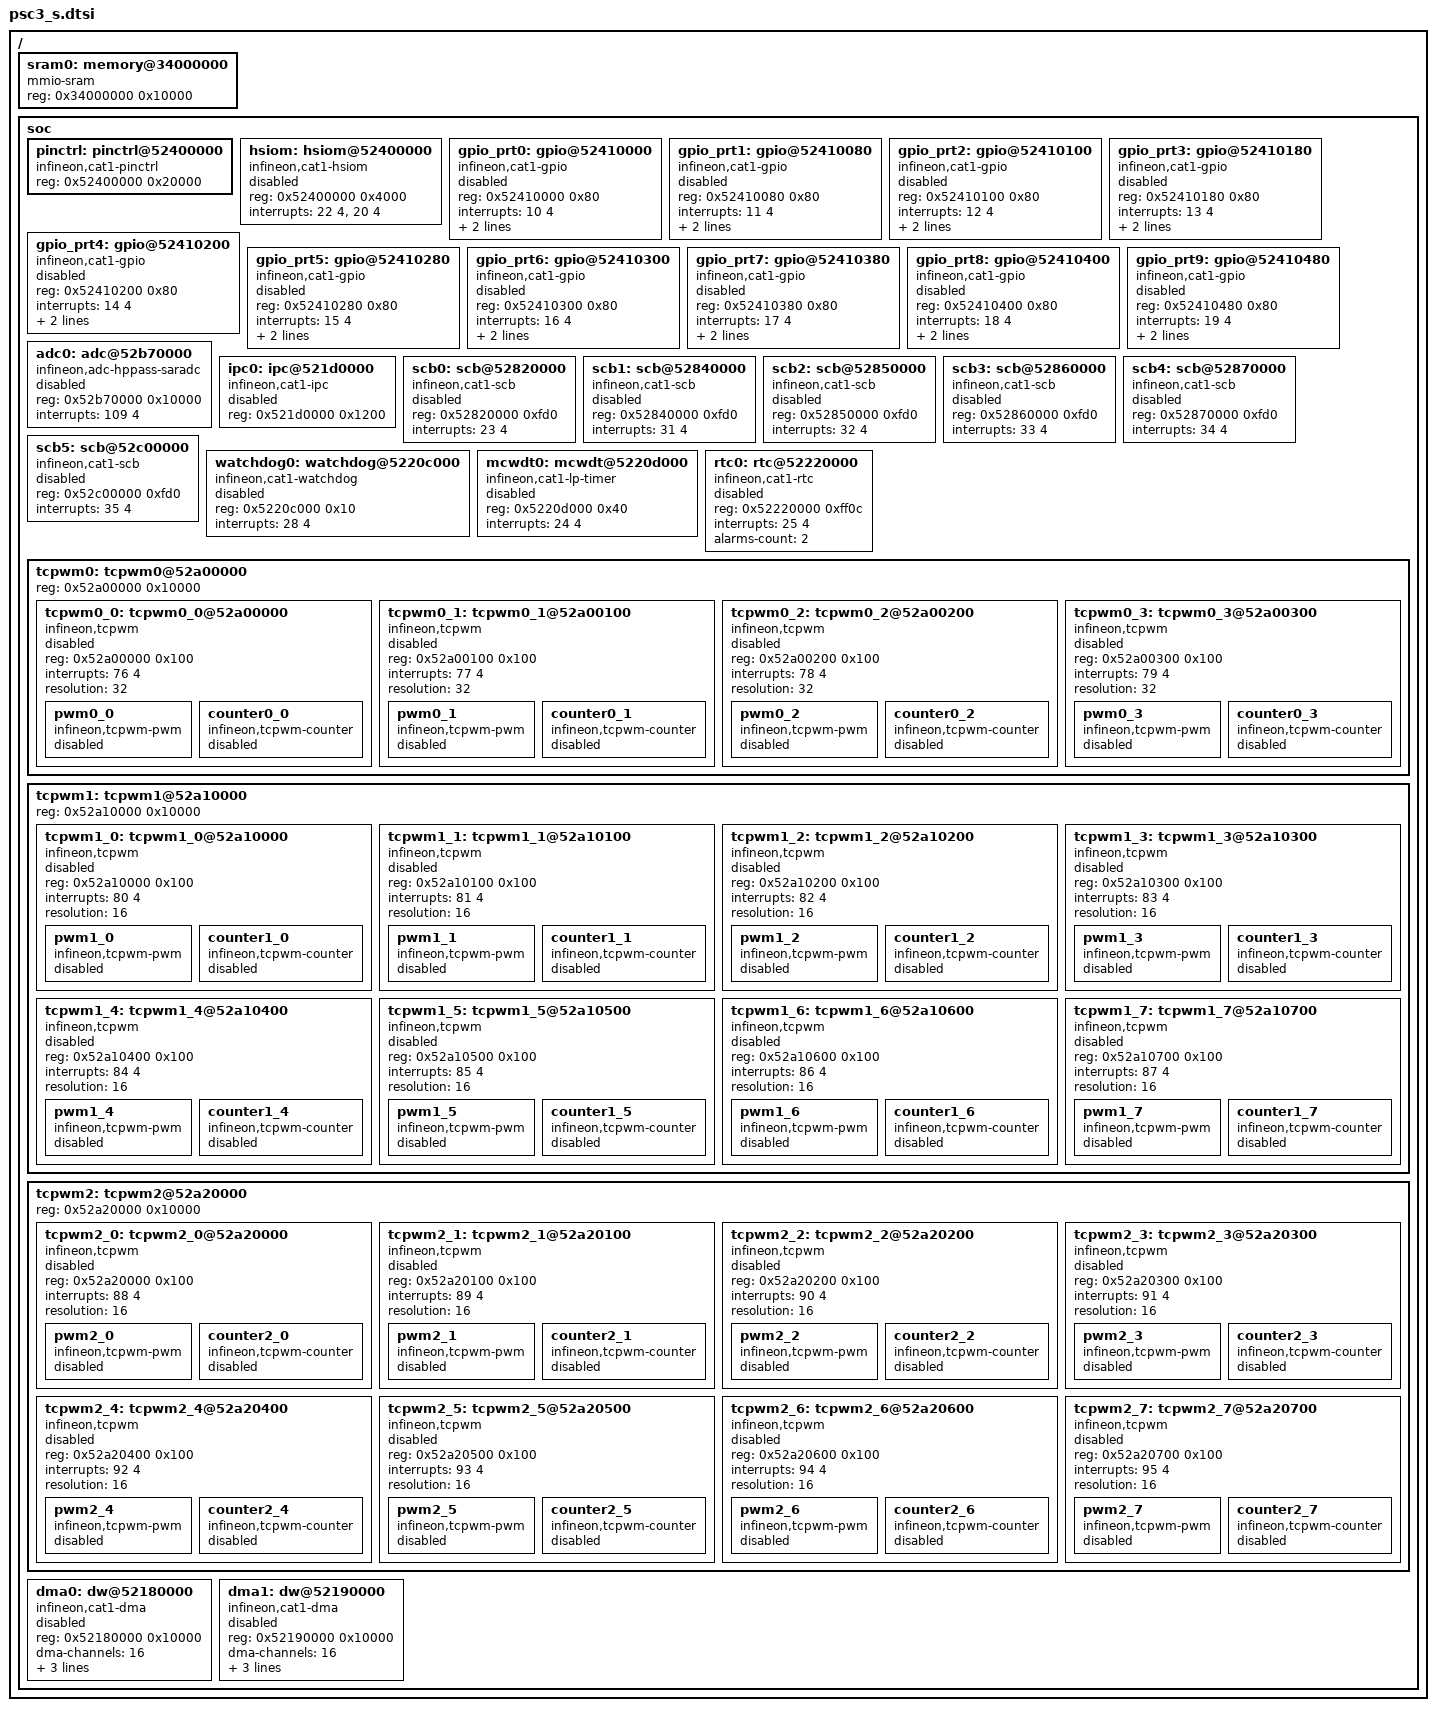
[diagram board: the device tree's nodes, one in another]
/*
 * copyright (c) (2016-2025), Cypress Semiconductor Corporation
 * (an Infineon company) or an affiliate of Cypress Semiconductor Corporation.
 *
 * SPDX-License-Identifier: Apache-2.0
 *
 */

#include <mem.h>
#include "psc3.cm33.dtsi"

/ {
	sram0: memory@34000000 {
		compatible = "mmio-sram";
		reg = <0x34000000 0x10000>;
	};

	soc {
		pinctrl: pinctrl@52400000 {
			compatible = "infineon,cat1-pinctrl";
			reg = <0x52400000 0x20000>;
		};

		hsiom: hsiom@52400000 {
			compatible = "infineon,cat1-hsiom";
			reg = <0x52400000 0x4000>;
			interrupts = <22 4>, <20 4>;
			status = "disabled";
		};

		gpio_prt0: gpio@52410000 {
			compatible = "infineon,cat1-gpio";
			reg = <0x52410000 0x80>;
			interrupts = <10 4>;
			gpio-controller;
			ngpios = <2>;
			status = "disabled";
			#gpio-cells = <2>;
		};

		gpio_prt1: gpio@52410080 {
			compatible = "infineon,cat1-gpio";
			reg = <0x52410080 0x80>;
			interrupts = <11 4>;
			gpio-controller;
			ngpios = <4>;
			status = "disabled";
			#gpio-cells = <2>;
		};

		gpio_prt2: gpio@52410100 {
			compatible = "infineon,cat1-gpio";
			reg = <0x52410100 0x80>;
			interrupts = <12 4>;
			gpio-controller;
			ngpios = <4>;
			status = "disabled";
			#gpio-cells = <2>;
		};

		gpio_prt3: gpio@52410180 {
			compatible = "infineon,cat1-gpio";
			reg = <0x52410180 0x80>;
			interrupts = <13 4>;
			gpio-controller;
			ngpios = <4>;
			status = "disabled";
			#gpio-cells = <2>;
		};

		gpio_prt4: gpio@52410200 {
			compatible = "infineon,cat1-gpio";
			reg = <0x52410200 0x80>;
			interrupts = <14 4>;
			gpio-controller;
			ngpios = <8>;
			status = "disabled";
			#gpio-cells = <2>;
		};

		gpio_prt5: gpio@52410280 {
			compatible = "infineon,cat1-gpio";
			reg = <0x52410280 0x80>;
			interrupts = <15 4>;
			gpio-controller;
			ngpios = <4>;
			status = "disabled";
			#gpio-cells = <2>;
		};

		gpio_prt6: gpio@52410300 {
			compatible = "infineon,cat1-gpio";
			reg = <0x52410300 0x80>;
			interrupts = <16 4>;
			gpio-controller;
			ngpios = <4>;
			status = "disabled";
			#gpio-cells = <2>;
		};

		gpio_prt7: gpio@52410380 {
			compatible = "infineon,cat1-gpio";
			reg = <0x52410380 0x80>;
			interrupts = <17 4>;
			gpio-controller;
			ngpios = <8>;
			status = "disabled";
			#gpio-cells = <2>;
		};

		gpio_prt8: gpio@52410400 {
			compatible = "infineon,cat1-gpio";
			reg = <0x52410400 0x80>;
			interrupts = <18 4>;
			gpio-controller;
			ngpios = <6>;
			status = "disabled";
			#gpio-cells = <2>;
		};

		gpio_prt9: gpio@52410480 {
			compatible = "infineon,cat1-gpio";
			reg = <0x52410480 0x80>;
			interrupts = <19 4>;
			gpio-controller;
			ngpios = <6>;
			status = "disabled";
			#gpio-cells = <2>;
		};

		adc0: adc@52b70000 {
			compatible = "infineon,adc-hppass-saradc";
			reg = <0x52b70000 0x10000>;
			interrupts = <109 4>;
			status = "disabled";
			#io-channel-cells = <1>;
		};

		ipc0: ipc@521d0000 {
			compatible = "infineon,cat1-ipc";
			reg = <0x521d0000 0x1200>;
			status = "disabled";
			#ipc-config-cells = <3>;
		};

		scb0: scb@52820000 {
			compatible = "infineon,cat1-scb";
			reg = <0x52820000 0xfd0>;
			interrupts = <23 4>;
			status = "disabled";
		};

		scb1: scb@52840000 {
			compatible = "infineon,cat1-scb";
			reg = <0x52840000 0xfd0>;
			interrupts = <31 4>;
			status = "disabled";
		};

		scb2: scb@52850000 {
			compatible = "infineon,cat1-scb";
			reg = <0x52850000 0xfd0>;
			interrupts = <32 4>;
			status = "disabled";
		};

		scb3: scb@52860000 {
			compatible = "infineon,cat1-scb";
			reg = <0x52860000 0xfd0>;
			interrupts = <33 4>;
			status = "disabled";
		};

		scb4: scb@52870000 {
			compatible = "infineon,cat1-scb";
			reg = <0x52870000 0xfd0>;
			interrupts = <34 4>;
			status = "disabled";
		};

		scb5: scb@52c00000 {
			compatible = "infineon,cat1-scb";
			reg = <0x52c00000 0xfd0>;
			interrupts = <35 4>;
			status = "disabled";
		};

		watchdog0: watchdog@5220c000 {
			compatible = "infineon,cat1-watchdog";
			reg = <0x5220c000 0x10>;
			interrupts = <28 4>;
			status = "disabled";
		};

		mcwdt0: mcwdt@5220d000 {
			compatible = "infineon,cat1-lp-timer";
			reg = <0x5220d000 0x40>;
			interrupts = <24 4>;
			status = "disabled";
		};

		rtc0: rtc@52220000 {
			compatible = "infineon,cat1-rtc";
			reg = <0x52220000 0xff0c>;
			interrupts = <25 4>;
			alarms-count = <2>;
			status = "disabled";
		};

		tcpwm0: tcpwm0@52a00000  {
			reg = <0x52a00000 0x10000>;
			#address-cells = <1>;
			#size-cells = <1>;

			tcpwm0_0: tcpwm0_0@52a00000 {
				compatible = "infineon,tcpwm";
				reg = <0x52a00000 0x100>;
				interrupts = <76 4>;
				resolution = <32>;
				status = "disabled";

				pwm0_0: pwm0_0 {
					compatible = "infineon,tcpwm-pwm";
					#pwm-cells = <3>;
					status = "disabled";
				};

				counter0_0: counter0_0 {
					compatible = "infineon,tcpwm-counter";
					status = "disabled";
				};
			};

			tcpwm0_1: tcpwm0_1@52a00100 {
				compatible = "infineon,tcpwm";
				reg = <0x52a00100 0x100>;
				interrupts = <77 4>;
				resolution = <32>;
				status = "disabled";

				pwm0_1: pwm0_1 {
					compatible = "infineon,tcpwm-pwm";
					#pwm-cells = <3>;
					status = "disabled";
				};

				counter0_1: counter0_1 {
					compatible = "infineon,tcpwm-counter";
					status = "disabled";
				};
			};

			tcpwm0_2: tcpwm0_2@52a00200 {
				compatible = "infineon,tcpwm";
				reg = <0x52a00200 0x100>;
				interrupts = <78 4>;
				resolution = <32>;
				status = "disabled";

				pwm0_2: pwm0_2 {
					compatible = "infineon,tcpwm-pwm";
					#pwm-cells = <3>;
					status = "disabled";
				};

				counter0_2: counter0_2 {
					compatible = "infineon,tcpwm-counter";
					status = "disabled";
				};
			};

			tcpwm0_3: tcpwm0_3@52a00300 {
				compatible = "infineon,tcpwm";
				reg = <0x52a00300 0x100>;
				interrupts = <79 4>;
				resolution = <32>;
				status = "disabled";

				pwm0_3: pwm0_3 {
					compatible = "infineon,tcpwm-pwm";
					#pwm-cells = <3>;
					status = "disabled";
				};

				counter0_3: counter0_3 {
					compatible = "infineon,tcpwm-counter";
					status = "disabled";
				};
			};
		};

		tcpwm1: tcpwm1@52a10000  {
			reg = <0x52a10000 0x10000>;
			#address-cells = <1>;
			#size-cells = <1>;

			tcpwm1_0: tcpwm1_0@52a10000 {
				compatible = "infineon,tcpwm";
				reg = <0x52a10000 0x100>;
				interrupts = <80 4>;
				resolution = <16>;
				status = "disabled";

				pwm1_0: pwm1_0 {
					compatible = "infineon,tcpwm-pwm";
					#pwm-cells = <3>;
					status = "disabled";
				};

				counter1_0: counter1_0 {
					compatible = "infineon,tcpwm-counter";
					status = "disabled";
				};
			};

			tcpwm1_1: tcpwm1_1@52a10100 {
				compatible = "infineon,tcpwm";
				reg = <0x52a10100 0x100>;
				interrupts = <81 4>;
				resolution = <16>;
				status = "disabled";

				pwm1_1: pwm1_1 {
					compatible = "infineon,tcpwm-pwm";
					#pwm-cells = <3>;
					status = "disabled";
				};

				counter1_1: counter1_1 {
					compatible = "infineon,tcpwm-counter";
					status = "disabled";
				};
			};

			tcpwm1_2: tcpwm1_2@52a10200 {
				compatible = "infineon,tcpwm";
				reg = <0x52a10200 0x100>;
				interrupts = <82 4>;
				resolution = <16>;
				status = "disabled";

				pwm1_2: pwm1_2 {
					compatible = "infineon,tcpwm-pwm";
					#pwm-cells = <3>;
					status = "disabled";
				};

				counter1_2: counter1_2 {
					compatible = "infineon,tcpwm-counter";
					status = "disabled";
				};
			};

			tcpwm1_3: tcpwm1_3@52a10300 {
				compatible = "infineon,tcpwm";
				reg = <0x52a10300 0x100>;
				interrupts = <83 4>;
				resolution = <16>;
				status = "disabled";

				pwm1_3: pwm1_3 {
					compatible = "infineon,tcpwm-pwm";
					#pwm-cells = <3>;
					status = "disabled";
				};

				counter1_3: counter1_3 {
					compatible = "infineon,tcpwm-counter";
					status = "disabled";
				};
			};

			tcpwm1_4: tcpwm1_4@52a10400 {
				compatible = "infineon,tcpwm";
				reg = <0x52a10400 0x100>;
				interrupts = <84 4>;
				resolution = <16>;
				status = "disabled";

				pwm1_4: pwm1_4 {
					compatible = "infineon,tcpwm-pwm";
					#pwm-cells = <3>;
					status = "disabled";
				};

				counter1_4: counter1_4 {
					compatible = "infineon,tcpwm-counter";
					status = "disabled";
				};
			};

			tcpwm1_5: tcpwm1_5@52a10500 {
				compatible = "infineon,tcpwm";
				reg = <0x52a10500 0x100>;
				interrupts = <85 4>;
				resolution = <16>;
				status = "disabled";

				pwm1_5: pwm1_5 {
					compatible = "infineon,tcpwm-pwm";
					#pwm-cells = <3>;
					status = "disabled";
				};

				counter1_5: counter1_5 {
					compatible = "infineon,tcpwm-counter";
					status = "disabled";
				};
			};

			tcpwm1_6: tcpwm1_6@52a10600 {
				compatible = "infineon,tcpwm";
				reg = <0x52a10600 0x100>;
				interrupts = <86 4>;
				resolution = <16>;
				status = "disabled";

				pwm1_6: pwm1_6 {
					compatible = "infineon,tcpwm-pwm";
					#pwm-cells = <3>;
					status = "disabled";
				};

				counter1_6: counter1_6 {
					compatible = "infineon,tcpwm-counter";
					status = "disabled";
				};
			};

			tcpwm1_7: tcpwm1_7@52a10700 {
				compatible = "infineon,tcpwm";
				reg = <0x52a10700 0x100>;
				interrupts = <87 4>;
				resolution = <16>;
				status = "disabled";

				pwm1_7: pwm1_7 {
					compatible = "infineon,tcpwm-pwm";
					#pwm-cells = <3>;
					status = "disabled";
				};

				counter1_7: counter1_7 {
					compatible = "infineon,tcpwm-counter";
					status = "disabled";
				};
			};
		};

		tcpwm2: tcpwm2@52a20000  {
			reg = <0x52a20000 0x10000>;
			#address-cells = <1>;
			#size-cells = <1>;

			tcpwm2_0: tcpwm2_0@52a20000 {
				compatible = "infineon,tcpwm";
				reg = <0x52a20000 0x100>;
				interrupts = <88 4>;
				resolution = <16>;
				status = "disabled";

				pwm2_0: pwm2_0 {
					compatible = "infineon,tcpwm-pwm";
					#pwm-cells = <3>;
					status = "disabled";
				};

				counter2_0: counter2_0 {
					compatible = "infineon,tcpwm-counter";
					status = "disabled";
				};
			};

			tcpwm2_1: tcpwm2_1@52a20100 {
				compatible = "infineon,tcpwm";
				reg = <0x52a20100 0x100>;
				interrupts = <89 4>;
				resolution = <16>;
				status = "disabled";

				pwm2_1: pwm2_1 {
					compatible = "infineon,tcpwm-pwm";
					#pwm-cells = <3>;
					status = "disabled";
				};

				counter2_1: counter2_1 {
					compatible = "infineon,tcpwm-counter";
					status = "disabled";
				};
			};

			tcpwm2_2: tcpwm2_2@52a20200 {
				compatible = "infineon,tcpwm";
				reg = <0x52a20200 0x100>;
				interrupts = <90 4>;
				resolution = <16>;
				status = "disabled";

				pwm2_2: pwm2_2 {
					compatible = "infineon,tcpwm-pwm";
					#pwm-cells = <3>;
					status = "disabled";
				};

				counter2_2: counter2_2 {
					compatible = "infineon,tcpwm-counter";
					status = "disabled";
				};
			};

			tcpwm2_3: tcpwm2_3@52a20300 {
				compatible = "infineon,tcpwm";
				reg = <0x52a20300 0x100>;
				interrupts = <91 4>;
				resolution = <16>;
				status = "disabled";

				pwm2_3: pwm2_3 {
					compatible = "infineon,tcpwm-pwm";
					#pwm-cells = <3>;
					status = "disabled";
				};

				counter2_3: counter2_3 {
					compatible = "infineon,tcpwm-counter";
					status = "disabled";
				};
			};

			tcpwm2_4: tcpwm2_4@52a20400 {
				compatible = "infineon,tcpwm";
				reg = <0x52a20400 0x100>;
				interrupts = <92 4>;
				resolution = <16>;
				status = "disabled";

				pwm2_4: pwm2_4 {
					compatible = "infineon,tcpwm-pwm";
					#pwm-cells = <3>;
					status = "disabled";
				};

				counter2_4: counter2_4 {
					compatible = "infineon,tcpwm-counter";
					status = "disabled";
				};
			};

			tcpwm2_5: tcpwm2_5@52a20500 {
				compatible = "infineon,tcpwm";
				reg = <0x52a20500 0x100>;
				interrupts = <93 4>;
				resolution = <16>;
				status = "disabled";

				pwm2_5: pwm2_5 {
					compatible = "infineon,tcpwm-pwm";
					#pwm-cells = <3>;
					status = "disabled";
				};

				counter2_5: counter2_5 {
					compatible = "infineon,tcpwm-counter";
					status = "disabled";
				};
			};

			tcpwm2_6: tcpwm2_6@52a20600 {
				compatible = "infineon,tcpwm";
				reg = <0x52a20600 0x100>;
				interrupts = <94 4>;
				resolution = <16>;
				status = "disabled";

				pwm2_6: pwm2_6 {
					compatible = "infineon,tcpwm-pwm";
					#pwm-cells = <3>;
					status = "disabled";
				};

				counter2_6: counter2_6 {
					compatible = "infineon,tcpwm-counter";
					status = "disabled";
				};
			};

			tcpwm2_7: tcpwm2_7@52a20700 {
				compatible = "infineon,tcpwm";
				reg = <0x52a20700 0x100>;
				interrupts = <95 4>;
				resolution = <16>;
				status = "disabled";

				pwm2_7: pwm2_7 {
					compatible = "infineon,tcpwm-pwm";
					#pwm-cells = <3>;
					status = "disabled";
				};

				counter2_7: counter2_7 {
					compatible = "infineon,tcpwm-counter";
					status = "disabled";
				};
			};
		};

		dma0: dw@52180000 {
			#dma-cells = <1>;
			compatible = "infineon,cat1-dma";
			reg = <0x52180000 0x10000>;
			dma-channels = <16>;
			interrupts = <37 4>, /* CH0 */
				     <38 4>, /* CH1 */
				     <39 4>, /* CH2 */
				     <40 4>, /* CH3 */
				     <41 4>, /* CH4 */
				     <42 4>, /* CH5 */
				     <43 4>, /* CH6 */
				     <44 4>, /* CH7 */
				     <45 4>, /* CH8 */
				     <46 4>, /* CH9 */
				     <47 4>, /* CH10 */
				     <48 4>, /* CH11 */
				     <49 4>, /* CH12 */
				     <50 4>, /* CH13 */
				     <51 4>, /* CH14 */
				     <52 4>; /* CH15 */
			status = "disabled";
		};

		dma1: dw@52190000 {
			#dma-cells = <1>;
			compatible = "infineon,cat1-dma";
			reg = <0x52190000 0x10000>;
			dma-channels = <16>;
			interrupts = <53 4>, /* CH0 */
				     <54 4>, /* CH1 */
				     <55 4>, /* CH2 */
				     <56 4>, /* CH3 */
				     <57 4>, /* CH4 */
				     <58 4>, /* CH5 */
				     <59 4>, /* CH6 */
				     <60 4>, /* CH7 */
				     <61 4>, /* CH8 */
				     <62 4>, /* CH9 */
				     <63 4>, /* CH10 */
				     <64 4>, /* CH11 */
				     <65 4>, /* CH12 */
				     <66 4>, /* CH13 */
				     <67 4>, /* CH14 */
				     <68 4>; /* CH15 */
			status = "disabled";
		};
	};
};
